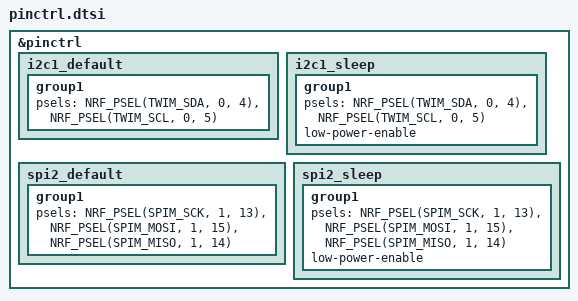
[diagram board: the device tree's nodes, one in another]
#include <zephyr/dt-bindings/pinctrl/nrf-pinctrl.h>

&pinctrl {
    // I2C1: SDA=P0.04 (D4), SCL=P0.05 (D5) - REVERTED TO STANDARD
    i2c1_default: i2c1_default {
        group1 {
            psels = <NRF_PSEL(TWIM_SDA, 0, 4)>,
                    <NRF_PSEL(TWIM_SCL, 0, 5)>;
        };
    };

    i2c1_sleep: i2c1_sleep {
        group1 {
            psels = <NRF_PSEL(TWIM_SDA, 0, 4)>,
                    <NRF_PSEL(TWIM_SCL, 0, 5)>;
            low-power-enable;
        };
    };

    // SPI2: SCK=P1.13 (D8), MISO=P1.14 (D9), MOSI=P1.15 (D10)
    spi2_default: spi2_default {
        group1 {
            psels = <NRF_PSEL(SPIM_SCK, 1, 13)>,
                    <NRF_PSEL(SPIM_MOSI, 1, 15)>,
                    <NRF_PSEL(SPIM_MISO, 1, 14)>;
        };
    };

    spi2_sleep: spi2_sleep {
        group1 {
            psels = <NRF_PSEL(SPIM_SCK, 1, 13)>,
                    <NRF_PSEL(SPIM_MOSI, 1, 15)>,
                    <NRF_PSEL(SPIM_MISO, 1, 14)>;
            low-power-enable;
        };
    };
};
